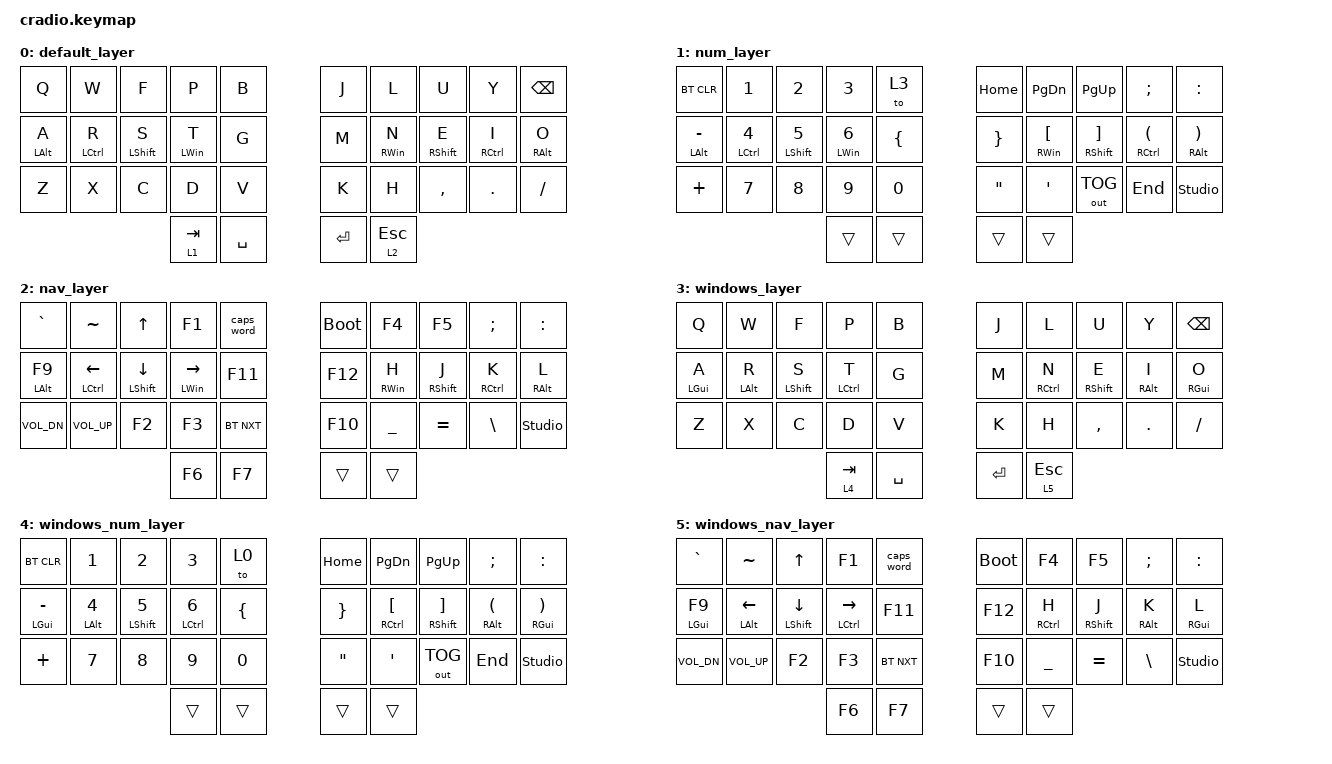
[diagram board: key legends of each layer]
// Copyright (c) 2022 The ZMK Contributors
// SPDX-License-Identifier: MIT

#include <behaviors.dtsi>
#include <dt-bindings/zmk/keys.h>
#include <dt-bindings/zmk/bt.h>
#include <dt-bindings/zmk/outputs.h>

/ {
    behaviors {
        ht: hold_tap {
            compatible = "zmk,behavior-hold-tap";
            #binding-cells = <2>;
            flavor = "tap-preferred";
            tapping-term-ms = <220>;
            quick-tap-ms = <150>;
            require-prior-idle-ms = <100>;
            bindings = <&kp>, <&kp>;
        };
    };

    keymap {
        compatible = "zmk,keymap";
        default_layer {
            bindings = <
     // 0 ╭──────────────┬──────────────┬──────────────┬──────────────┬──────────────╮   ╭──────────────┬──────────────┬──────────────┬──────────────┬──────────────╮
            &kp Q          &kp W          &kp F          &kp P          &kp B              &kp J          &kp L          &kp U          &kp Y          &kp BSPC
        //├──────────────┼──────────────┼──────────────┼──────────────┼──────────────┤   ├──────────────┼──────────────┼──────────────┼──────────────┼──────────────┤
            &ht LALT A     &ht LCTRL R    &ht LSHFT S    &ht LWIN T     &kp G              &kp M          &ht RWIN N     &ht RSHFT E    &ht RCTRL I    &ht RALT O
        //├──────────────┼──────────────┼──────────────┼──────────────┼──────────────┤   ├──────────────┼──────────────┼──────────────┼──────────────┼──────────────┤
            &kp Z          &kp X          &kp C          &kp D          &kp V              &kp K          &kp H          &kp COMMA      &kp DOT        &kp FSLH
        //╰──────────────┴──────────────┴──────────────┼──────────────┼──────────────┤   ├──────────────┼──────────────┼──────────────┴──────────────┴──────────────╯
                                                         &lt 1 TAB      &kp SPACE          &kp ENTER      &lt 2 ESC
        //                                             ╰──────────────┴──────────────╯   ╰──────────────┴──────────────╯
            >;
        };

        num_layer {
            bindings = <
     // 1 ╭──────────────┬──────────────┬──────────────┬──────────────┬──────────────╮   ╭──────────────┬──────────────┬──────────────┬──────────────┬──────────────╮
            &bt BT_CLR     &kp N1         &kp N2         &kp N3         &to 3              &kp HOME       &kp PG_DN      &kp PG_UP      &kp SEMI       &kp COLON
        //├──────────────┼──────────────┼──────────────┼──────────────┼──────────────┤   ├──────────────┼──────────────┼──────────────┼──────────────┼──────────────┤
            &ht LALT MINUS &ht LCTRL N4   &ht LSHFT N5   &ht LWIN N6    &kp LBRC           &kp RBRC       &ht RWIN LBKT  &ht RSHFT RBKT &ht RCTRL LPAR &ht RALT RPAR
        //├──────────────┼──────────────┼──────────────┼──────────────┼──────────────┤   ├──────────────┼──────────────┼──────────────┼──────────────┼──────────────┤
            &kp PLUS       &kp N7         &kp N8         &kp N9         &kp N0             &kp DQT        &kp SQT        &out OUT_TOG   &kp END        &studio_unlock
        //╰──────────────┴──────────────┴──────────────┼──────────────┼──────────────┤   ├──────────────┼──────────────┼──────────────┴──────────────┴──────────────╯
                                                         &trans         &trans             &trans         &trans
        //                                             ╰──────────────┴──────────────╯   ╰──────────────┴──────────────╯
            >;
        };

        nav_layer {
            bindings = <
     // 2 ╭──────────────┬──────────────┬──────────────┬──────────────┬──────────────╮   ╭──────────────┬──────────────┬──────────────┬──────────────┬──────────────╮
            &kp GRAVE      &kp TILDE      &kp UP         &kp F1         &caps_word         &bootloader    &kp F4         &kp F5         &kp SEMI       &kp COLON
        //├──────────────┼──────────────┼──────────────┼──────────────┼──────────────┤   ├──────────────┼──────────────┼──────────────┼──────────────┼──────────────┤
            &ht LALT F9    &ht LCTRL LEFT &ht LSHFT DOWN &ht LWIN RIGHT &kp F11            &kp F12        &ht RWIN H     &ht RSHFT J    &ht RCTRL K    &ht RALT L
        //├──────────────┼──────────────┼──────────────┼──────────────┼──────────────┤   ├──────────────┼──────────────┼──────────────┼──────────────┼──────────────┤
            &kp K_VOL_DN   &kp K_VOL_UP   &kp F2         &kp F3         &bt BT_NXT         &kp F10        &kp UNDER      &kp EQUAL      &kp BSLH       &studio_unlock
        //╰──────────────┴──────────────┴──────────────┼──────────────┼──────────────┤   ├──────────────┼──────────────┼──────────────┴──────────────┴──────────────╯
                                                         &kp F6         &kp F7             &trans         &trans
        //                                             ╰──────────────┴──────────────╯   ╰──────────────┴──────────────╯
            >;
        };

        windows_layer {
            bindings = <
     // 3 ╭──────────────┬──────────────┬──────────────┬──────────────┬──────────────╮   ╭──────────────┬──────────────┬──────────────┬──────────────┬──────────────╮
            &kp Q          &kp W          &kp F          &kp P          &kp B              &kp J          &kp L          &kp U          &kp Y          &kp BSPC
        //├──────────────┼──────────────┼──────────────┼──────────────┼──────────────┤   ├──────────────┼──────────────┼──────────────┼──────────────┼──────────────┤
            &ht LGUI A     &ht LALT R     &ht LSHFT S    &ht LCTRL T    &kp G              &kp M          &ht RCTRL N    &ht RSHFT E    &ht RALT I     &ht RGUI O
        //├──────────────┼──────────────┼──────────────┼──────────────┼──────────────┤   ├──────────────┼──────────────┼──────────────┼──────────────┼──────────────┤
            &kp Z          &kp X          &kp C          &kp D          &kp V              &kp K          &kp H          &kp COMMA      &kp DOT        &kp FSLH
        //╰──────────────┴──────────────┴──────────────┼──────────────┼──────────────┤   ├──────────────┼──────────────┼──────────────┴──────────────┴──────────────╯
                                                         &lt 4 TAB      &kp SPACE          &kp ENTER      &lt 5 ESC
        //                                             ╰──────────────┴──────────────╯   ╰──────────────┴──────────────╯
            >;
        };

        windows_num_layer {
            bindings = <
     // 4 ╭──────────────┬──────────────┬──────────────┬──────────────┬──────────────╮   ╭──────────────┬──────────────┬──────────────┬──────────────┬──────────────╮
            &bt BT_CLR     &kp N1         &kp N2         &kp N3         &to 0              &kp HOME       &kp PG_DN      &kp PG_UP      &kp SEMI       &kp COLON
        //├──────────────┼──────────────┼──────────────┼──────────────┼──────────────┤   ├──────────────┼──────────────┼──────────────┼──────────────┼──────────────┤
            &ht LGUI MINUS &ht LALT N4    &ht LSHFT N5   &ht LCTRL N6   &kp LBRC           &kp RBRC       &ht RCTRL LBKT &ht RSHFT RBKT &ht RALT LPAR  &ht RGUI RPAR
        //├──────────────┼──────────────┼──────────────┼──────────────┼──────────────┤   ├──────────────┼──────────────┼──────────────┼──────────────┼──────────────┤
            &kp PLUS       &kp N7         &kp N8         &kp N9         &kp N0             &kp DQT        &kp SQT        &out OUT_TOG   &kp END        &studio_unlock
        //╰──────────────┴──────────────┴──────────────┼──────────────┼──────────────┤   ├──────────────┼──────────────┼──────────────┴──────────────┴──────────────╯
                                                         &trans         &trans             &trans         &trans
        //                                             ╰──────────────┴──────────────╯   ╰──────────────┴──────────────╯
            >;
        };

        windows_nav_layer {
            bindings = <
     // 5 ╭──────────────┬──────────────┬──────────────┬──────────────┬──────────────╮   ╭──────────────┬──────────────┬──────────────┬──────────────┬──────────────╮
            &kp GRAVE      &kp TILDE      &kp UP         &kp F1         &caps_word         &bootloader    &kp F4         &kp F5         &kp SEMI       &kp COLON
        //├──────────────┼──────────────┼──────────────┼──────────────┼──────────────┤   ├──────────────┼──────────────┼──────────────┼──────────────┼──────────────┤
            &ht LGUI F9    &ht LALT LEFT  &ht LSHFT DOWN &ht LCTRL RIGHT&kp F11            &kp F12        &ht RCTRL H    &ht RSHFT J    &ht RALT K     &ht RGUI L
        //├──────────────┼──────────────┼──────────────┼──────────────┼──────────────┤   ├──────────────┼──────────────┼──────────────┼──────────────┼──────────────┤
            &kp C_VOL_DN   &kp C_VOL_UP   &kp F2         &kp F3         &bt BT_NXT         &kp F10        &kp UNDER      &kp EQUAL      &kp BSLH       &studio_unlock
        //╰──────────────┴──────────────┴──────────────┼──────────────┼──────────────┤   ├──────────────┼──────────────┼──────────────┴──────────────┴──────────────╯
                                                         &kp F6         &kp F7             &trans         &trans
        //                                             ╰──────────────┴──────────────╯   ╰──────────────┴──────────────╯
            >;
        };
    };
};
